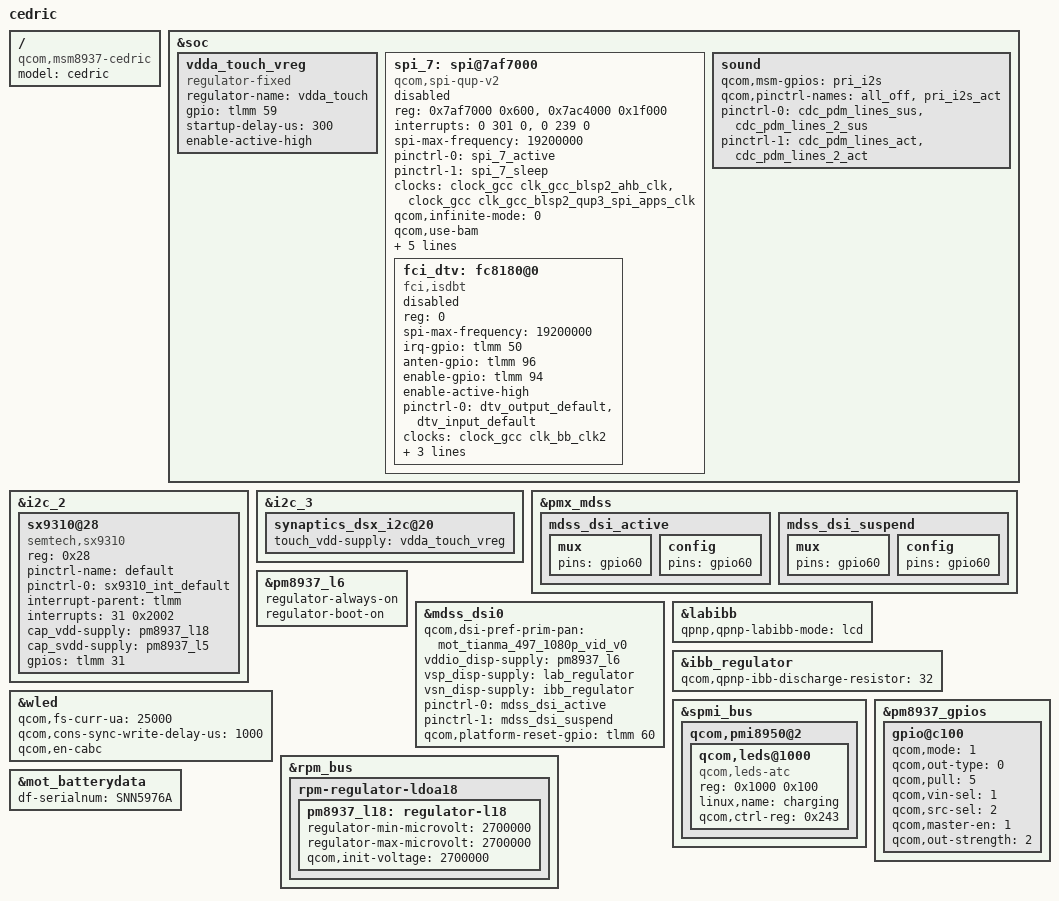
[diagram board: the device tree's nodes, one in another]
/* Copyright (c) 2016, Motorola Mobility Inc. All rights reserved.
 *
 * This program is free software; you can redistribute it and/or modify
 * it under the terms of the GNU General Public License version 2 and
 * only version 2 as published by the Free Software Foundation.
 *
 * This program is distributed in the hope that it will be useful,
 * but WITHOUT ANY WARRANTY; without even the implied warranty of
 * MERCHANTABILITY or FITNESS FOR A PARTICULAR PURPOSE.  See the
 * GNU General Public License for more details.
 */

#include "msm8937-moto-common.dtsi"
#include "dsi-panel-mot-tianma-497-1080p-video.dtsi"

 / {
	model = "cedric";
	compatible = "qcom,msm8937-cedric", "qcom,msm8937-moto",
			"qcom,msm8937";
};

&soc {
	vdda_touch_vreg: vdda_touch_vreg {
		compatible = "regulator-fixed";
		regulator-name = "vdda_touch";
		gpio = <&tlmm 59 0>;
		startup-delay-us = <300>;
		enable-active-high;
	};

	spi_7: spi@7af7000 { /* BLSP2 QUP2 */
		compatible = "qcom,spi-qup-v2";
		#address-cells = <1>;
		#size-cells = <0>;
		reg-names = "spi_physical", "spi_bam_physical";
		reg = <0x7af7000 0x600>,
		       <0x7ac4000 0x1f000>;
		interrupt-names = "spi_irq", "spi_bam_irq";
		/* IRQ 239 for BLSP2 */
		interrupts = <0 301 0>, <0 239 0>;
		spi-max-frequency = <19200000>;
		pinctrl-names = "spi_default", "spi_sleep";
		pinctrl-0 = <&spi_7_active>;
		pinctrl-1 = <&spi_7_sleep>;
		clocks = <&clock_gcc clk_gcc_blsp2_ahb_clk>,
			 <&clock_gcc clk_gcc_blsp2_qup3_spi_apps_clk>;
		clock-names = "iface_clk", "core_clk";
		qcom,infinite-mode = <0>;
		qcom,use-bam;
		qcom,use-pinctrl;
		qcom,ver-reg-exists;
		/* need to check pipe index setting*/
		qcom,bam-consumer-pipe-index = <8>;
		qcom,bam-producer-pipe-index = <9>;
		/* master-id for BLSP2 is MSM_BUS_MASTER_BLSP_2 or 84 */
		qcom,master-id = <84>;
		status = "/chosen", "mmi,dtv", "true";
		fci_dtv: fc8180@0 {
			status = "/chosen", "mmi,dtv", "true";
			compatible = "fci,isdbt";
			reg = <0>;
			spi-max-frequency = <19200000>;
			irq-gpio = <&tlmm 50 0>;
			anten-gpio = <&tlmm 96 0>;
			enable-gpio = <&tlmm 94 0>;
			enable-active-high;
			pinctrl-names = "default";
			pinctrl-0 = <&dtv_output_default &dtv_input_default>;
			clocks = <&clock_gcc clk_bb_clk2>;
			clock-names = "dtv_refclk";
			isdbt_vdd-supply = <&pm8937_l6>;
			qcom,vdd-min-max-voltage = <1800000 1800000>;
			qcom,bbm-xtal-freq = <26000>;


		};
	};

	sound {
		/delete-property/ qcom,cdc-us-euro-gpios;
		/delete-property/ qcom,msm-micbias1-ext-cap;

		qcom,msm-gpios =
			"pri_i2s";
		qcom,pinctrl-names =
			"all_off",
			"pri_i2s_act";
		pinctrl-names =
			"all_off",
			"pri_i2s_act";
		pinctrl-0 = <&cdc_pdm_lines_sus &cdc_pdm_lines_2_sus>;
		pinctrl-1 = <&cdc_pdm_lines_act &cdc_pdm_lines_2_act>;
		/delete-property/ pinctrl-2;
		/delete-property/ pinctrl-3;
		/delete-property/ pinctrl-4;
		/delete-property/ pinctrl-5;
		/delete-property/ pinctrl-6;
		/delete-property/ pinctrl-7;
	};
};

&i2c_2 {
	sx9310@28 {
		compatible = "semtech,sx9310";
		reg = <0x28>;
		pinctrl-name = "default";
		pinctrl-0 = <&sx9310_int_default>;
		interrupt-parent = <&tlmm>;
		interrupts = <31 0x2002>;
		cap_vdd-supply = <&pm8937_l18>;
		cap_svdd-supply = <&pm8937_l5>;
		gpios = <&tlmm 31 0x2008>; /* IRQ */
	};
};


&i2c_3 {
	synaptics_dsx_i2c@20 {
		touch_vdd-supply = <&vdda_touch_vreg>;
	};
};

&pmx_mdss {
	mdss_dsi_active {
		mux {
			pins = "gpio60";
		};

		config {
			pins = "gpio60";
		};
	};

	mdss_dsi_suspend {
		mux {
			pins = "gpio60";
		};

		config {
			pins = "gpio60";
		};
	};
};

&pm8937_l6 {
        regulator-always-on;
        regulator-boot-on;
};

&mdss_dsi0 {
	qcom,dsi-pref-prim-pan = <&mot_tianma_497_1080p_vid_v0>;
	vddio_disp-supply = <&pm8937_l6>;
	vsp_disp-supply = <&lab_regulator>;
	vsn_disp-supply = <&ibb_regulator>;

	pinctrl-names = "mdss_default", "mdss_sleep";
	pinctrl-0 = <&mdss_dsi_active>;
	pinctrl-1 = <&mdss_dsi_suspend>;

	qcom,platform-reset-gpio = <&tlmm 60 0>;
};

/* display boost and inverting boost regulators */
&labibb {
	status = "ok";
	qpnp,qpnp-labibb-mode = "lcd";
};

&ibb_regulator {
	qcom,qpnp-ibb-discharge-resistor = <32>;
};

&wled {
	qcom,fs-curr-ua = <25000>;
	qcom,cons-sync-write-delay-us = <1000>;
	qcom,en-cabc;
};

&spmi_bus {
	qcom,pmi8950@2 {
		/delete-node/ qcom,leds@a100;

		qcom,leds@1000 {
			status = "ok";
			reg = <0x1000 0x100>;
			compatible = "qcom,leds-atc";
			linux,name = "charging";
			qcom,ctrl-reg = <0x243>;
		};
	};
};

&pm8937_gpios {
	gpio@c100 {
		status = "ok";
		qcom,mode = <1>;
		qcom,out-type = <0>;
		qcom,pull = <5>;
		qcom,vin-sel = <1>;
		qcom,src-sel = <2>;
		qcom,master-en = <1>;
		qcom,out-strength = <2>;
	};
};

&rpm_bus {
	rpm-regulator-ldoa18 {
		status = "okay";
		pm8937_l18: regulator-l18 {
			regulator-min-microvolt = <2700000>;
			regulator-max-microvolt = <2700000>;
			qcom,init-voltage = <2700000>;
			status = "okay";
		};
	};
};

&mot_batterydata {
	df-serialnum = "SNN5976A";
	#include "batterydata-gk40-atl.dtsi"
};
